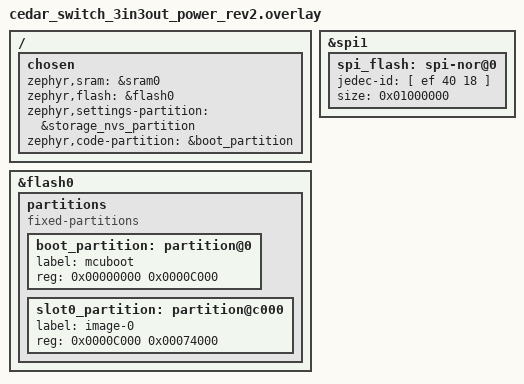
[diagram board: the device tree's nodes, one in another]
/ {
	chosen {
		//		zephyr,console = &usart2;
		//		zephyr,shell-uart = &usart2;
		zephyr,sram = &sram0;
		zephyr,flash = &flash0;
		zephyr,settings-partition = &storage_nvs_partition;
		zephyr,code-partition = &boot_partition;
	};
};

&flash0 {
	partitions {
		compatible = "fixed-partitions";
		#address-cells = <1>;
		#size-cells = <1>;

		boot_partition: partition@0 {
			label = "mcuboot";
			reg = <0x00000000 0x0000C000>; /* 32 KB */
		};

		/* Основное приложение */
		slot0_partition: partition@c000 {
			label = "image-0";
			reg = <0x0000C000 0x00074000>; /* 464 KB (512K - 48K) */
		};
	};
};

&spi1 {
	spi_flash: spi-nor@0 {
		jedec-id = [ ef 40 18 ];       /* Winbond W25Q128JV (128Mbit / 16MB) */
		size = <0x01000000>;             /* 128 Мбит = 16 МБ (в битах!) */
	};

};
